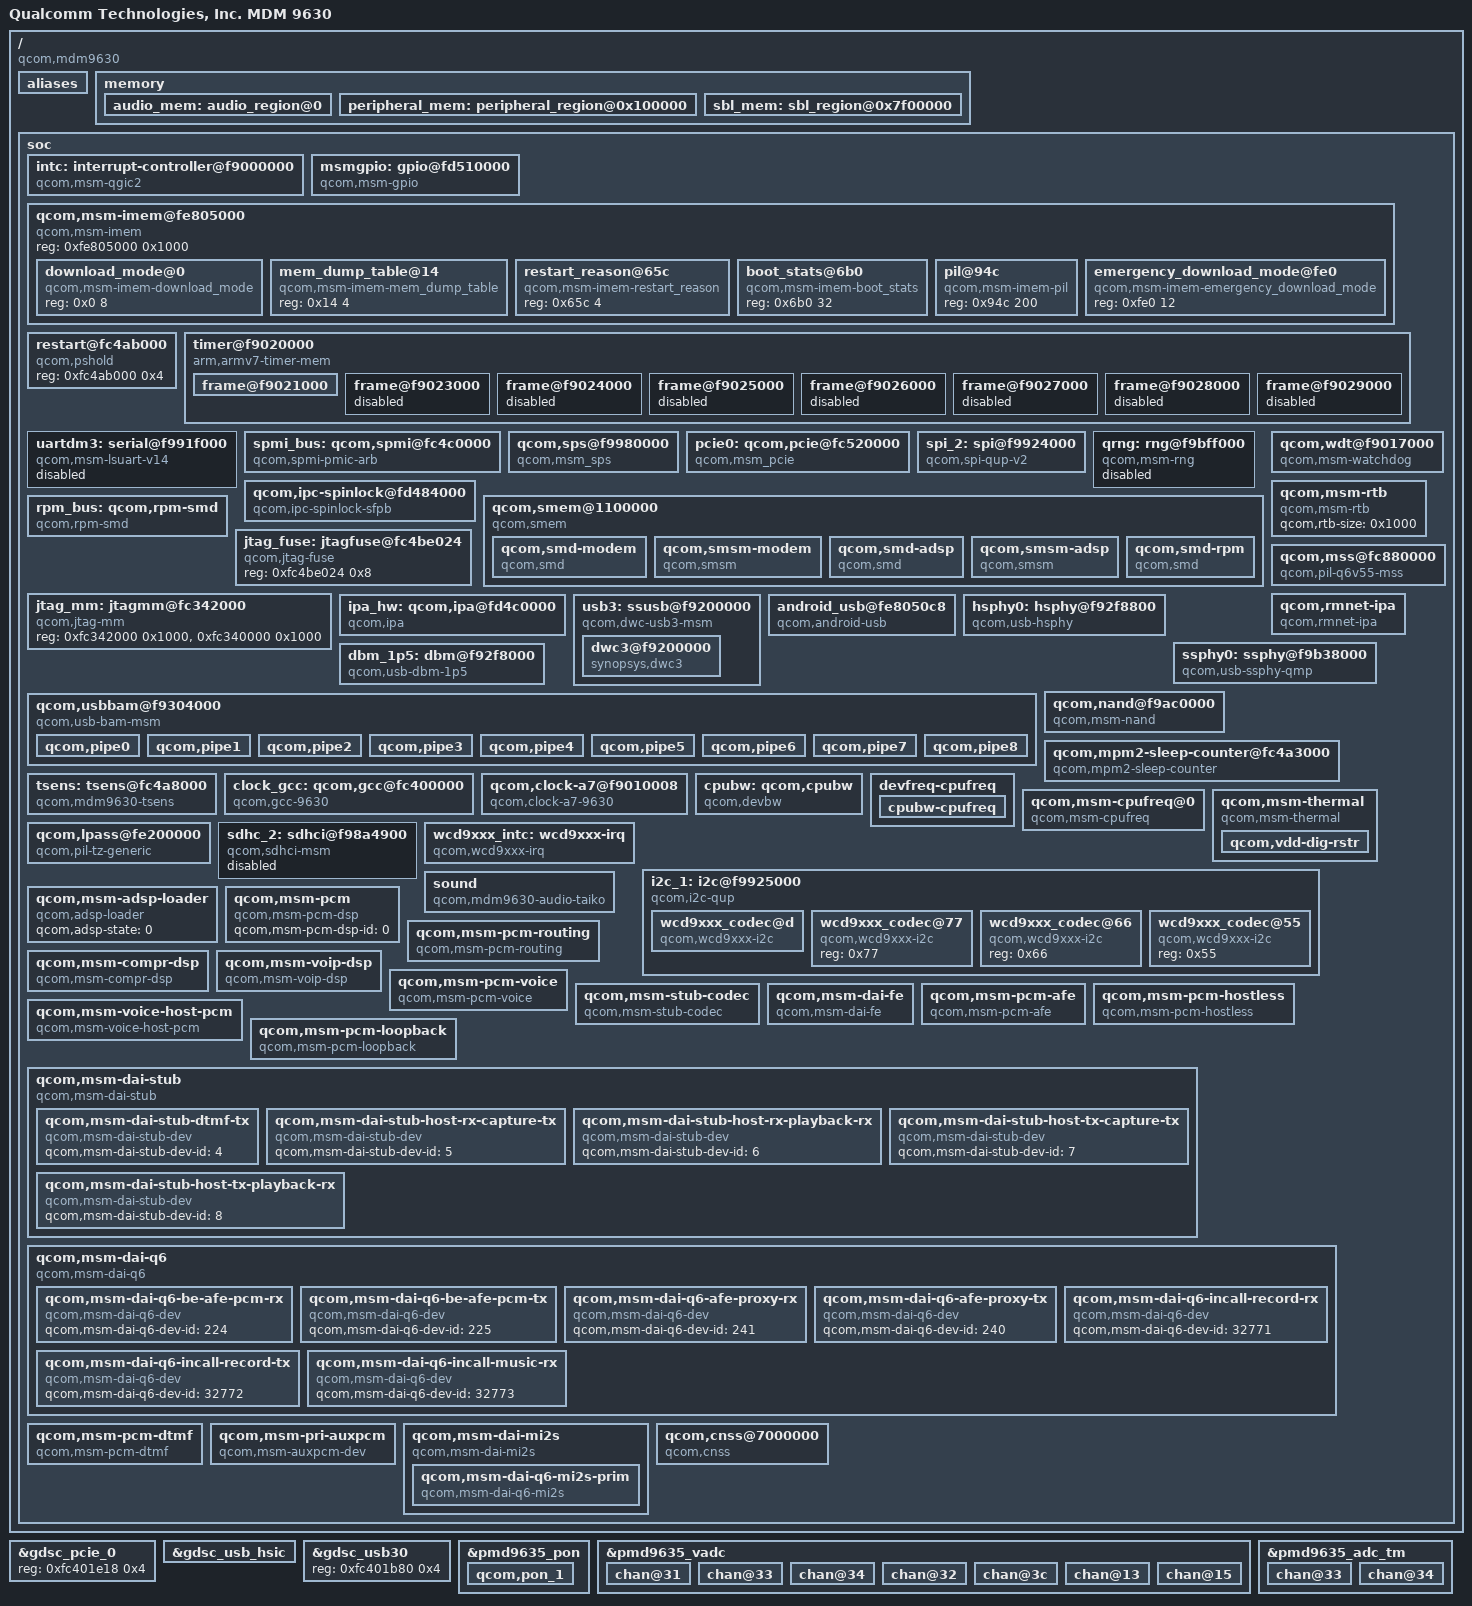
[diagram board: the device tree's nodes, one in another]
/* Copyright (c) 2013-2014, The Linux Foundation. All rights reserved.
 *
 * This program is free software; you can redistribute it and/or modify
 * it under the terms of the GNU General Public License version 2 and
 * only version 2 as published by the Free Software Foundation.
 *
 * This program is distributed in the hope that it will be useful,
 * but WITHOUT ANY WARRANTY; without even the implied warranty of
 * MERCHANTABILITY or FITNESS FOR A PARTICULAR PURPOSE.  See the
 * GNU General Public License for more details.
 */

#include "skeleton.dtsi"

/ {
	model = "Qualcomm Technologies, Inc. MDM 9630";
	compatible = "qcom,mdm9630";
	qcom,msm-id = <187 0x10000>, <227 0x10000>, <228 0x10000>,
		      <229 0x10000>, <230 0x10000>, <231 0x10000>;
	interrupt-parent = <&intc>;

	aliases {
		spi2 = &spi_2;
		sdhc2 = &sdhc_2; /* SDC2 SD card slot */
	};

	memory {
		audio_mem: audio_region@0 {
			linux,reserve-contiguous-region;
			linux,reserve-region;
			reg = <0 0xAF000>;
			label = "audio_mem";
		};

		peripheral_mem: peripheral_region@0x100000 {
			linux,reserve-contiguous-region;
			linux,reserve-region;
			linux,remove-completely;
			reg = <0x1000000 0x6100000>;
			label = "peripheral_mem";
		};

		sbl_mem: sbl_region@0x7f00000 {
			linux,reserve-contiguous-region;
			linux,reserve-region;
			linux,remove-completely;
			reg = <0x7f00000 0x100000>;
			label = "sbl_mem";
		};
	};

	soc: soc { };
};

#include "mdm9630-smp2p.dtsi"
#include "mdm9630-coresight.dtsi"
#include "msm-gdsc.dtsi"
#include "mdm9630-pm.dtsi"
#include "mdm9630-bus.dtsi"
#include "mdm9630-ion.dtsi"
#include "mdm9630-pinctrl.dtsi"

&soc {
	#address-cells = <1>;
	#size-cells = <1>;
	ranges;

	intc: interrupt-controller@f9000000 {
		compatible = "qcom,msm-qgic2";
		interrupt-controller;
		#interrupt-cells = <3>;
		reg = <0xf9000000 0x1000>,
		      <0xf9002000 0x1000>;
	};

	msmgpio: gpio@fd510000 {
		compatible = "qcom,msm-gpio";
		gpio-controller;
		#gpio-cells = <2>;
		interrupt-controller;
		#interrupt-cells = <2>;
		reg = <0xfd510000 0x4000>;
		ngpio = <90>;
		interrupts = <0 208 0>;
		qcom,direct-connect-irqs = <8>;
	};

	qcom,msm-imem@fe805000 {
		compatible = "qcom,msm-imem";
		reg = <0xfe805000 0x1000>; /* Address and size of IMEM */
		ranges = <0x0 0xfe805000 0x1000>;
		#address-cells = <1>;
		#size-cells = <1>;

		download_mode@0 {
			compatible = "qcom,msm-imem-download_mode";
			reg = <0x0 8>;
		};

		mem_dump_table@14 {
			compatible = "qcom,msm-imem-mem_dump_table";
			reg = <0x14 4>;
		};

		restart_reason@65c {
			compatible = "qcom,msm-imem-restart_reason";
			reg = <0x65c 4>;
		};

		boot_stats@6b0 {
			compatible = "qcom,msm-imem-boot_stats";
			reg = <0x6b0 32>;
		};

		pil@94c {
			compatible = "qcom,msm-imem-pil";
			reg = <0x94c 200>;
		};

		emergency_download_mode@fe0 {
			compatible = "qcom,msm-imem-emergency_download_mode";
			reg = <0xfe0 12>;
		};
	};

	restart@fc4ab000 {
		compatible = "qcom,pshold";
		reg = <0xfc4ab000 0x4>;
	};

	timer@f9020000 {
		#address-cells = <1>;
		#size-cells = <1>;
		ranges;
		compatible = "arm,armv7-timer-mem";
		reg = <0xf9020000 0x1000>;
		clock-frequency = <19200000>;

		frame@f9021000 {
			frame-number = <0>;
			interrupts = <0 7 0x4>,
				     <0 6 0x4>;
			reg = <0xf9021000 0x1000>,
			      <0xf9022000 0x1000>;
		};

		frame@f9023000 {
			frame-number = <1>;
			interrupts = <0 8 0x4>;
			reg = <0xf9023000 0x1000>;
			status = "disabled";
		};

		frame@f9024000 {
			frame-number = <2>;
			interrupts = <0 9 0x4>;
			reg = <0xf9024000 0x1000>;
			status = "disabled";
		};

		frame@f9025000 {
			frame-number = <3>;
			interrupts = <0 10 0x4>;
			reg = <0xf9025000 0x1000>;
			status = "disabled";
		};

		frame@f9026000 {
			frame-number = <4>;
			interrupts = <0 11 0x4>;
			reg = <0xf9026000 0x1000>;
			status = "disabled";
		};

		frame@f9027000 {
			frame-number = <5>;
			interrupts = <0 12 0x4>;
			reg = <0xf9027000 0x1000>;
			status = "disabled";
		};

		frame@f9028000 {
			frame-number = <6>;
			interrupts = <0 13 0x4>;
			reg = <0xf9028000 0x1000>;
			status = "disabled";
		};

		frame@f9029000 {
			frame-number = <7>;
			interrupts = <0 14 0x4>;
			reg = <0xf9029000 0x1000>;
			status = "disabled";
		};
	};

	uartdm3: serial@f991f000 {
		compatible = "qcom,msm-lsuart-v14";
		reg = <0xf991f000 0x1000>;
		interrupts = <0 109 0>;
		status = "disabled";
	};

	spmi_bus: qcom,spmi@fc4c0000 {
		compatible = "qcom,spmi-pmic-arb";
		reg = <0xfc4cf000 0x1000>,
		      <0Xfc4cb000 0x1000>,
		      <0Xfc4ca000 0x1000>;
		reg-names = "core", "intr", "cnfg";
		interrupts = <0 190 0>;
		qcom,pmic-arb-channel = <0>;
		qcom,pmic-arb-ee = <0>;
		#interrupt-cells = <3>;
		interrupt-controller;
		#address-cells = <1>;
		#size-cells = <0>;
		cell-index = <0>;
	};

	qcom,sps@f9980000 {
		compatible = "qcom,msm_sps";
		reg = <0xf9984000 0x15000>,
		      <0xf9999000 0xb000>,
		      <0xfe803000 0xd000>,
			  <0xfe805000 0x1000>;
		interrupts = <0 94 0>;
	};

	pcie0: qcom,pcie@fc520000 {
		compatible = "qcom,msm_pcie";
		cell-index = <0>;
		qcom,ctrl-amt = <1>;

		reg = <0xfc520000 0x2000>,
		      <0xfc526000 0x1000>,
		      <0x80000000 0x1000>,
		      <0x80001000 0x1000>,
		      <0x80100000 0x1000>,
		      <0x80200000 0x100000>,
		      <0x80300000 0xd00000>;
		reg-names = "parf", "phy", "dm_core", "elbi",
				"conf", "io", "bars";

		#address-cells = <0>;
		interrupt-parent = <&pcie0>;
		interrupts = <0 1 2 3 4 5 6 7 8 9 10 11 12>;
		#interrupt-cells = <1>;
		interrupt-map-mask = <0xffffffff>;
		interrupt-map = <0 &intc 0 41 0
				1 &intc 0 42 0
				2 &intc 0 43 0
				3 &intc 0 44 0
				4 &intc 0 45 0
				5 &intc 0 46 0
				6 &intc 0 47 0
				7 &intc 0 48 0
				8 &intc 0 49 0
				9 &intc 0 50 0
				10 &intc 0 51 0
				11 &intc 0 52 0
				12 &msmgpio 65 0x2>;
		interrupt-names = "int_msi", "int_a", "int_b", "int_c", "int_d",
				"int_pls_pme", "int_pme_legacy", "int_pls_err",
				"int_aer_legacy", "int_pls_link_up",
				"int_pls_link_down", "int_bridge_flush_n",
				"int_wake";

		perst-gpio = <&msmgpio 61 0>;
		wake-gpio = <&msmgpio 65 0>;
		clkreq-gpio = <&msmgpio 64 0>;

		gdsc-vdd-supply = <&gdsc_pcie_0>;
		vreg-1.8-supply = <&pmd9635_l8>;
		vreg-0.9-supply = <&pmd9635_l4>;

		qcom,vreg-1.8-voltage-level = <1800000 1800000 1000>;
		qcom,vreg-0.9-voltage-level = <950000 950000 24000>;

		clock-names = "pcie_0_pipe_clk", "pcie_0_ref_clk_src",
				"pcie_0_aux_clk", "pcie_0_cfg_ahb_clk",
				"pcie_0_mstr_axi_clk", "pcie_0_slv_axi_clk",
				"pcie_0_ldo";
		max-clock-frequency-hz = <125000000>, <0>, <1000000>,
						<0>, <0>, <0>, <0>;

		qcom,msm-bus,name = "pcie0";
		qcom,msm-bus,num-cases = <2>;
		qcom,msm-bus,num-paths = <1>;
		qcom,msm-bus,vectors-KBps =
				<45 512 0 0>,
				<45 512 500 800>;
	};

	spi_2: spi@f9924000 { /* BLSP1 QUP2 */
		compatible = "qcom,spi-qup-v2";
		#address-cells = <1>;
		#size-cells = <0>;
		reg-names = "spi_physical", "spi_bam_physical";
		reg = <0xf9924000 0x1000>,
		      <0xf9904000 0x19000>;
		interrupt-names = "spi_irq", "spi_bam_irq";
		interrupts = <0 96 0>, <0 238 0>;
		spi-max-frequency = <2400000>;

		qcom,gpio-mosi = <&msmgpio 4 0>;
		qcom,gpio-miso = <&msmgpio 5 0>;
		qcom,gpio-clk  = <&msmgpio 7 0>;
		qcom,gpio-cs0  = <&msmgpio 6 0>;

		qcom,infinite-mode = <0>;
		qcom,use-bam;
		qcom,ver-reg-exists;
		qcom,bam-consumer-pipe-index = <14>;
		qcom,bam-producer-pipe-index = <15>;
		qcom,master-id = <86>;
	};

	qrng: rng@f9bff000 {
		compatible = "qcom,msm-rng";
		reg = <0xf9bff000 0x200>;
		qcom,msm-rng-iface-clk;
		qcom,msm-bus,name = "msm-rng-noc";
		qcom,msm-bus,num-cases = <2>;
		qcom,msm-bus,num-paths = <1>;
		qcom,msm-bus,vectors-KBps =
				<1 618 0 0>,
				<1 618 0 800>;
		status = "disabled";
	};

	qcom,ipc-spinlock@fd484000 {
		compatible = "qcom,ipc-spinlock-sfpb";
		reg = <0xfd484000 0x400>;
		qcom,num-locks = <8>;
	};

	qcom,smem@1100000 {
		compatible = "qcom,smem";
		reg = <0x1100000 0x100000>,
			<0xf9011000 0x1000>,
			<0xfc428000 0x4000>;
		reg-names = "smem", "irq-reg-base", "aux-mem1";
		qcom,mpu-enabled;

		qcom,smd-modem {
			compatible = "qcom,smd";
			qcom,smd-edge = <0>;
			qcom,smd-irq-offset = <0x8>;
			qcom,smd-irq-bitmask = <0x1000>;
			interrupts = <0 25 1>;
			label = "modem";
		};

		qcom,smsm-modem {
			compatible = "qcom,smsm";
			qcom,smsm-edge = <0>;
			qcom,smsm-irq-offset = <0x8>;
			qcom,smsm-irq-bitmask = <0x2000>;
			interrupts = <0 26 1>;
		};

		qcom,smd-adsp {
			compatible = "qcom,smd";
			qcom,smd-edge = <1>;
			qcom,smd-irq-offset = <0x8>;
			qcom,smd-irq-bitmask = <0x100>;
			interrupts = <0 156 1>;
			label = "adsp";
		};

		qcom,smsm-adsp {
			compatible = "qcom,smsm";
			qcom,smsm-edge = <1>;
			qcom,smsm-irq-offset = <0x8>;
			qcom,smsm-irq-bitmask = <0x200>;
			interrupts = <0 157 1>;
		};

		qcom,smd-rpm {
			compatible = "qcom,smd";
			qcom,smd-edge = <15>;
			qcom,smd-irq-offset = <0x8>;
			qcom,smd-irq-bitmask = <0x1>;
			interrupts = <0 168 1>;
			label = "rpm";
			qcom,irq-no-suspend;
			qcom,not-loadable;
		};
	};

	rpm_bus: qcom,rpm-smd {
		compatible = "qcom,rpm-smd";
		rpm-channel-name = "rpm_requests";
		rpm-channel-type = <15>; /* SMD_APPS_RPM */
	};

	qcom,wdt@f9017000 {
		compatible = "qcom,msm-watchdog";
		reg = <0xf9017000 0x1000>;
		reg-names = "wdt-base";
		interrupts = <1 2 0>, <1 1 0>;
		qcom,bark-time = <11000>;
		qcom,pet-time = <10000>;
	};

	jtag_fuse: jtagfuse@fc4be024 {
		compatible = "qcom,jtag-fuse";
		reg = <0xfc4be024 0x8>;
		reg-names = "fuse-base";
	};

	jtag_mm: jtagmm@fc342000 {
		compatible = "qcom,jtag-mm";
		reg = <0xfc342000 0x1000>,
		      <0xfc340000 0x1000>;
		reg-names = "etm-base","debug-base";
	};

	qcom,msm-rtb {
		compatible = "qcom,msm-rtb";
		qcom,rtb-size = <0x1000>; /* 4K EBI1 buffer */
	};

	qcom,mss@fc880000 {
		compatible = "qcom,pil-q6v55-mss";
		reg = <0xfc880000 0x100>,
		      <0xfd485000 0x400>,
		      <0xfc820000 0x020>,
		      <0xfc401680 0x004>;
		reg-names = "qdsp6_base", "halt_base", "rmb_base",
			    "restart_reg";

		interrupts = <0 24 1>;
		vdd_mss-supply = <&pmd9635_s1>;
		vdd_cx-supply = <&pmd9635_l3_corner>;
		vdd_mx-supply = <&pmd9635_s3>;
		vdd_mx-uV = <7>;
		vdd_pll-supply = <&pmd9635_l7>;
		qcom,vdd_pll = <1800000>;

		qcom,firmware-name = "modem";
		qcom,pil-self-auth;
		qcom,mba-image-is-not-elf;

		/* GPIO inputs from mss */
		qcom,gpio-err-fatal = <&smp2pgpio_ssr_smp2p_1_in 0 0>;
		qcom,gpio-err-ready = <&smp2pgpio_ssr_smp2p_1_in 1 0>;
		qcom,gpio-proxy-unvote = <&smp2pgpio_ssr_smp2p_1_in 2 0>;
		qcom,gpio-stop-ack = <&smp2pgpio_ssr_smp2p_1_in 3 0>;

		/* GPIO output to mss */
		qcom,gpio-force-stop = <&smp2pgpio_ssr_smp2p_1_out 0 0>;
	};

	ipa_hw: qcom,ipa@fd4c0000 {
		compatible = "qcom,ipa";
		reg = <0xfd4c0000 0x29000>,
		      <0xfd4c4000 0x15820>;
		reg-names = "ipa-base", "bam-base";
		interrupts = <0 252 0>,
		             <0 254 0>;
		interrupt-names = "ipa-irq", "bam-irq";
		qcom,ipa-hw-ver = <3>; /* IPA core version = IPAv2.0 */
		qcom,ipa-hw-mode = <0>; /* IPA hw type = Normal */
		qcom,ee = <2>;
		qcom,use-ipa-tethering-bridge;
	};

	qcom,rmnet-ipa {
		compatible = "qcom,rmnet-ipa";
	};

	usb3: ssusb@f9200000 {
		compatible = "qcom,dwc-usb3-msm";
		reg = <0xf9200000 0xfc000>,
				<0xfd4ab000 0x4>;
		#address-cells = <1>;
		#size-cells = <1>;
		ranges;

		interrupt-parent = <&usb3>;
		interrupts = <0 1 2>;
		#interrupt-cells = <1>;
		interrupt-map-mask = <0x0 0xffffffff>;
		interrupt-map = <0x0 0 &intc 0 133 0
				 0x0 1 &intc 0 180 0
				 0x0 2 &spmi_bus 0x0 0x0 0x9 0x0>;
		interrupt-names = "hs_phy_irq", "pwr_event_irq",
				"pmic_id_irq";

		USB3_GDSC-supply = <&gdsc_usb30>;
		qcom,otg-capability;
		qcom,suspend_event_enable;
		qcom,usb-dbm = <&dbm_1p5>;

		qcom,msm-bus,name = "usb3";
		qcom,msm-bus,num-cases = <2>;
		qcom,msm-bus,num-paths = <1>;
		qcom,msm-bus,vectors-KBps =
						<61 512 0 0>,
						<61 512 240000 960000>;
		qcom,reset_hsphy_sleep_clk_on_init;
		qcom,power-collapse-on-cable-disconnect;
		qcom,por-after-power-collapse;

		dwc3@f9200000 {
				compatible = "synopsys,dwc3";
				reg = <0xf9200000 0xfc000>;
				interrupt-parent = <&intc>;
				interrupts = <0 131 0>, <0 179 0>;
				interrupt-names = "irq", "otg_irq";
				usb-phy = <&hsphy0>, <&ssphy0>;
				snps,nominal-elastic-buffer;
				snps,core-reset-after-phy-init;
				snps,hsphy-auto-suspend-disable;
				snps,hird_thresh = <0x10>;
		};
        };

	android_usb@fe8050c8 {
		reg = <0xfe8050c8 0xc8>;
		compatible = "qcom,android-usb";
		qcom,android-usb-swfi-latency = <100>;
	};

	hsphy0: hsphy@f92f8800 {
		compatible = "qcom,usb-hsphy";
		reg = <0xf92f8800 0x3ff>;
		qcom,hsphy-init = <0x00D191A4>;
		vdd-supply = <&pmd9635_l3_corner>;
		vdda18-supply = <&pmd9635_l8>;
		vdda33-supply = <&pmd9635_l10>;
		qcom,vdd-voltage-level = <1 5 7>;
		qcom,ext-vbus-id;
		qcom,vbus-valid-override;
		qcom,set-pllbtune;
	};

	ssphy0: ssphy@f9b38000 {
		compatible = "qcom,usb-ssphy-qmp";
		reg = <0xf9b38000 0x16c>,
			<0xf9b3e000 0x3ff>;
		reg-names = "qmp_phy_base",
			"qmp_ahb2phy_base";
		vdd-supply = <&pmd9635_l4>;
		vdda18-supply = <&pmd9635_l8>;
		qcom,vdd-voltage-level = <0 900000 1050000>;
		qcom,vbus-valid-override;
		qcom,ext-vbus-id;
	};

	dbm_1p5: dbm@f92f8000 {
		compatible = "qcom,usb-dbm-1p5";
		reg = <0xf92f8000 0x1000>;
		qcom,reset-ep-after-lpm-resume;
	};

	qcom,usbbam@f9304000 {
		compatible = "qcom,usb-bam-msm";
		reg = <0xf9304000 0x8814>;
		reg-names = "ssusb";
		interrupts = <0 132 0>;
		interrupt-names = "ssusb";
		qcom,usb-bam-fifo-baseaddr = <0xfe803000>;
		qcom,usb-bam-num-pipes = <16>;
		qcom,ignore-core-reset-ack;
		qcom,disable-clk-gating;
		qcom,usb-bam-override-threshold = <0x4001>;
		qcom,usb-bam-max-mbps-highspeed = <400>;
		qcom,usb-bam-max-mbps-superspeed = <3600>;

		qcom,pipe0 {
			label = "ssusb-ipa-out-0";
			qcom,usb-bam-mem-type = <2>;
			qcom,bam-type = <0>;
			qcom,dir = <0>;
			qcom,pipe-num = <0>;
			qcom,peer-bam = <2>;
			qcom,src-bam-physical-address = <0xf9304000>;
			qcom,src-bam-pipe-index = <1>;
			qcom,data-fifo-size = <0x8000>;
			qcom,descriptor-fifo-size = <0x2000>;
			qcom,reset-bam-on-connect;
			qcom,pipe-connection-type = <1>;
		};
		qcom,pipe1 {
			label = "ssusb-ipa-in-0";
			qcom,usb-bam-mem-type = <2>;
			qcom,bam-type = <0>;
			qcom,dir = <1>;
			qcom,pipe-num = <0>;
			qcom,peer-bam = <2>;
			qcom,dst-bam-physical-address = <0xf9304000>;
			qcom,dst-bam-pipe-index = <0>;
			qcom,data-fifo-size = <0x8000>;
			qcom,descriptor-fifo-size = <0x2000>;
			qcom,reset-bam-on-connect;
		};
		qcom,pipe2 {
			label = "ssusb-qdss-in-0";
			qcom,usb-bam-mem-type = <3>;
			qcom,bam-type = <0>;
			qcom,dir = <1>;
			qcom,pipe-num = <0>;
			qcom,peer-bam = <1>;
			qcom,src-bam-physical-address = <0xfc37C000>;
			qcom,src-bam-pipe-index = <0>;
			qcom,dst-bam-physical-address = <0xf9304000>;
			qcom,dst-bam-pipe-index = <2>;
			qcom,data-fifo-offset = <0x0>;
			qcom,data-fifo-size = <0xC00>;
			qcom,descriptor-fifo-offset = <0xC00>;
			qcom,descriptor-fifo-size = <0x400>;
			qcom,reset-bam-on-connect;
		};
		qcom,pipe3 {
			label = "ssusb-ipa-out-1";
			qcom,usb-bam-mem-type = <2>;
			qcom,bam-type = <0>;
			qcom,dir = <0>;
			qcom,pipe-num = <1>;
			qcom,peer-bam = <2>;
			qcom,src-bam-physical-address = <0xf9304000>;
			qcom,src-bam-pipe-index = <3>;
			qcom,data-fifo-size = <0x8000>;
			qcom,descriptor-fifo-size = <0x2000>;
			qcom,reset-bam-on-connect;
			qcom,pipe-connection-type = <1>;
		};
		qcom,pipe4 {
			label = "ssusb-ipa-in-1";
			qcom,usb-bam-mem-type = <2>;
			qcom,bam-type = <0>;
			qcom,dir = <1>;
			qcom,pipe-num = <1>;
			qcom,peer-bam = <2>;
			qcom,dst-bam-physical-address = <0xf9304000>;
			qcom,dst-bam-pipe-index = <2>;
			qcom,data-fifo-size = <0x8000>;
			qcom,descriptor-fifo-size = <0x2000>;
			qcom,reset-bam-on-connect;
		};
		qcom,pipe5 {
			label = "ssusb-ipa-out-2";
			qcom,usb-bam-mem-type = <2>;
			qcom,bam-type = <0>;
			qcom,dir = <0>;
			qcom,pipe-num = <2>;
			qcom,peer-bam = <2>;
			qcom,src-bam-physical-address = <0xf9304000>;
			qcom,src-bam-pipe-index = <5>;
			qcom,data-fifo-size = <0x8000>;
			qcom,descriptor-fifo-size = <0x2000>;
			qcom,reset-bam-on-connect;
			qcom,pipe-connection-type = <1>;
		};
		qcom,pipe6 {
			label = "ssusb-ipa-in-2";
			qcom,usb-bam-mem-type = <2>;
			qcom,bam-type = <0>;
			qcom,dir = <1>;
			qcom,pipe-num = <2>;
			qcom,peer-bam = <2>;
			qcom,dst-bam-physical-address = <0xf9304000>;
			qcom,dst-bam-pipe-index = <4>;
			qcom,data-fifo-size = <0x8000>;
			qcom,descriptor-fifo-size = <0x2000>;
			qcom,reset-bam-on-connect;
		};
		qcom,pipe7  {
			label = "ssusb-ipa-out-3";
			qcom,usb-bam-mem-type = <2>;
			qcom,bam-type = <0>;
			qcom,dir = <0>;
			qcom,pipe-num = <3>;
			qcom,peer-bam = <2>;
			qcom,src-bam-physical-address = <0xf9304000>;
			qcom,src-bam-pipe-index = <6>;
			qcom,data-fifo-size = <0x8000>;
			qcom,descriptor-fifo-size = <0x2000>;
			qcom,reset-bam-on-connect;
			qcom,pipe-connection-type = <1>;
		};
		qcom,pipe8  {
			label = "ssusb-ipa-in-3";
			qcom,usb-bam-mem-type = <2>;
			qcom,bam-type = <0>;
			qcom,dir = <1>;
			qcom,pipe-num = <3>;
			qcom,peer-bam = <2>;
			qcom,dst-bam-physical-address = <0xf9304000>;
			qcom,dst-bam-pipe-index = <7>;
			qcom,data-fifo-size = <0x8000>;
			qcom,descriptor-fifo-size = <0x2000>;
			qcom,reset-bam-on-connect;
		};
	};

	qcom,nand@f9ac0000 {
		compatible = "qcom,msm-nand";
		reg = <0xf9ac0000 0x1000>,
		      <0xf9ac4000 0x8000>;
		reg-names = "nand_phys",
			    "bam_phys";
		interrupts = <0 247 0>;
		interrupt-names = "bam_irq";

		qcom,msm-bus,name = "qpic_nand";
		qcom,msm-bus,num-cases = <2>;
		qcom,msm-bus,num-paths = <1>;

		qcom,msm-bus,vectors-KBps =
			<91 512 0 0>,
			/* Voting for max b/w on PNOC bus for now */
			<91 512 400000 800000>;

	};

	qcom,mpm2-sleep-counter@fc4a3000 {
		compatible = "qcom,mpm2-sleep-counter";
		reg = <0xfc4a3000 0x1000>;
		clock-frequency = <32768>;
	};

	tsens: tsens@fc4a8000 {
		compatible = "qcom,mdm9630-tsens";
		reg = <0xfc4a8000 0x2000>,
		      <0xfc4bc000 0x1000>;
		reg-names = "tsens_physical", "tsens_eeprom_physical";
		interrupts = <0 184 0>;
		qcom,sensors = <5>;
		qcom,slope = <2901 2846 3200 3200 3200>;
	};

	clock_gcc: qcom,gcc@fc400000 {
		compatible = "qcom,gcc-9630";
		reg = <0xfc400000 0x4000>,
			<0xf9011000 0x1C>,
			<0xf9008018 0x28>;
		reg-names = "cc_base", "meas", "apcs_base";
		vdd_dig-supply = <&pmd9635_l3_corner>;
		vdd_dig_ao-supply = <&pmd9635_l3_corner_ao>;
	};

	qcom,clock-a7@f9010008 {
		compatible = "qcom,clock-a7-9630";
		reg = <0xf9010008 0x8>;
		reg-names = "rcg-base";

		clock-names = "clk-1", "clk-5";
		qcom,speed0-bin-v0 =
			<         0 0>,
			< 300000000 4>,
			< 787200000 5>,
			<1152000000 7>;

		cpu-vdd-supply = <&pmd9635_l3_corner_ao>;
	};

	cpubw: qcom,cpubw {
		compatible = "qcom,devbw";
		governor = "cpufreq";
		qcom,src-dst-ports = <1 512>;
		qcom,active-only;
		qcom,bw-tbl =
			< 1266 /* 166 MHz */ >,
			< 2540 /* 333 MHz */ >,
			< 3051 /* 400 MHz */ >;
	};

	devfreq-cpufreq {
		cpubw-cpufreq {
			target-dev = <&cpubw>;
			cpu-to-dev-map =
				<  600000 1266 >,
				<  787200 2540 >,
				< 1152000 3051 >;
		};
	};

	qcom,msm-cpufreq@0 {
		reg = <0 4>;
		compatible = "qcom,msm-cpufreq";
		qcom,cpufreq-table =
			<  300000 >,
			<  600000 >,
			<  787200 >,
			<  998400 >,
			< 1152000 >;
	};

	qcom,msm-thermal {
		compatible = "qcom,msm-thermal";
		qcom,sensor-id = <0>;
		qcom,poll-ms = <250>;
		qcom,limit-temp = <60>;
		qcom,temp-hysteresis = <10>;
		qcom,freq-step = <2>;
		qcom,freq-control-mask = <0x0>;
		qcom,mx-restriction-temp = <5>;
		qcom,mx-restriction-temp-hysteresis = <5>;
		qcom,mx-retention-min = <710000>;
		vdd-mx-supply = <&pmd9635_s3>;
		qcom,vdd-restriction-temp = <5>;
		qcom,vdd-restriction-temp-hysteresis = <10>;
		vdd-dig-supply = <&pmd9635_l3_corner>;

		qcom,vdd-dig-rstr{
			qcom,vdd-rstr-reg = "vdd-dig";
			qcom,levels = <5 7 7>; /* Nominal, Super Turbo, Super Turbo */
			qcom,min-level = <1>; /* No Request */
		};
	};

	qcom,lpass@fe200000 {
		compatible = "qcom,pil-tz-generic";
		reg = <0xfe200000 0x00100>;
		interrupts = <0 162 1>;

		vdd_cx-supply = <&pmd9635_l3_corner>;
		qcom,proxy-reg-names = "vdd_cx";
		qcom,vdd_cx-uV-uA = <7 100000>;
		clock-names = "bus_clk", "xo", "scm_core_clk", "scm_iface_clk",
				"scm_bus_clk", "scm_core_clk_src";
		qcom,active-clock-names = "bus_clk";
		qcom,proxy-clock-names = "xo", "scm_core_clk", "scm_iface_clk",
					"scm_bus_clk", "scm_core_clk_src";
		qcom,scm_core_clk_src-freq = <85710000>;

		qcom,pas-id = <1>;
		qcom,proxy-timeout-ms = <10000>;
		qcom,smem-id = <423>;
		qcom,firmware-name = "adsp";

		/* GPIO inputs from lpass */
		qcom,gpio-err-fatal = <&smp2pgpio_ssr_smp2p_2_in 0 0>;
		qcom,gpio-proxy-unvote = <&smp2pgpio_ssr_smp2p_2_in 2 0>;
		qcom,gpio-err-ready = <&smp2pgpio_ssr_smp2p_2_in 1 0>;
		qcom,gpio-stop-ack = <&smp2pgpio_ssr_smp2p_2_in 3 0>;

		/* GPIO output to lpass */
		qcom,gpio-force-stop = <&smp2pgpio_ssr_smp2p_2_out 0 0>;
	};

	sdhc_2: sdhci@f98a4900 {
		compatible = "qcom,sdhci-msm";
		reg = <0xf98a4900 0x11c>, <0xf98a4000 0x800>;
		reg-names = "hc_mem", "core_mem";
		interrupts = <0 125 0>, <0 221 0>;
		interrupt-names = "hc_irq", "pwr_irq";

		qcom,clk-rates = <400000 20000000 25000000 50000000 100000000 200000000>;
		qcom,bus-width = <4>;
		qcom,cpu-dma-latency-us = <200>;
		status = "disable";
	};

	wcd9xxx_intc: wcd9xxx-irq {
		compatible = "qcom,wcd9xxx-irq";
		interrupt-controller;
		#interrupt-cells = <1>;
		interrupt-parent = <&msmgpio>;
		interrupts = <43 0>;
		interrupt-names = "cdc-int";
	};

	i2c_1: i2c@f9925000 { /* BLSP1 QUP3 */
		cell-index = <1>;
		compatible = "qcom,i2c-qup";
		#address-cells = <1>;
		#size-cells = <0>;
		reg-names = "qup_phys_addr";
		reg = <0xf9925000 0x1000>;
		interrupt-names = "qup_err_intr";
		interrupts = <0 97 0>;
		qcom,i2c-bus-freq = <400000>;
		qcom,i2c-src-freq = <19200000>;
		qcom,sda-gpio = <&msmgpio 10 0>;
		qcom,scl-gpio = <&msmgpio 11 0>;
		qcom,master-id = <86>;

		wcd9xxx_codec@d{
			compatible = "qcom,wcd9xxx-i2c";
			reg = <0x0d>;
			qcom,cdc-reset-gpio = <&msmgpio 67 0>;
			interrupt-parent = <&wcd9xxx_intc>;
			interrupts = <0 1 2 3 4 5 6 7 8 9 10 11 12 13 14 15 16 17 18 19 20 21 22 23 24 25 26 27 28>;
			cdc-vdd-buck-supply = <&pmd9635_s4>;
			qcom,cdc-vdd-buck-voltage = <1800000 1800000>;
			qcom,cdc-vdd-buck-current = <25000>;

			cdc-vdd-tx-h-supply = <&pmd9635_l15>;
			qcom,cdc-vdd-tx-h-voltage = <1800000 1800000>;
			qcom,cdc-vdd-tx-h-current = <25000>;

			cdc-vdd-rx-h-supply = <&pmd9635_l15>;
			qcom,cdc-vdd-rx-h-voltage = <1800000 1800000>;
			qcom,cdc-vdd-rx-h-current = <25000>;

			cdc-vddpx-1-supply = <&pmd9635_l6>;
			qcom,cdc-vddpx-1-voltage = <1800000 1800000>;
			qcom,cdc-vddpx-1-current = <10000>;

			cdc-vdd-a-1p2v-supply = <&pmd9635_l1>;
			qcom,cdc-vdd-a-1p2v-voltage = <1225000 1225000>;
			qcom,cdc-vdd-a-1p2v-current = <10000>;

			cdc-vddcx-1-supply = <&pmd9635_l2>;
			qcom,cdc-vddcx-1-voltage = <1200000 1200000>;
			qcom,cdc-vddcx-1-current = <10000>;

			cdc-vddcx-2-supply = <&pmd9635_l2>;
			qcom,cdc-vddcx-2-voltage = <1200000 1200000>;
			qcom,cdc-vddcx-2-current = <10000>;

			qcom,cdc-static-supplies = "cdc-vdd-buck",
						   "cdc-vdd-tx-h",
						   "cdc-vdd-rx-h",
						   "cdc-vddpx-1",
						   "cdc-vdd-a-1p2v",
						   "cdc-vddcx-1",
						   "cdc-vddcx-2";

			qcom,cdc-micbias-ldoh-v = <0x3>;
			qcom,cdc-micbias-cfilt1-mv = <1800>;
			qcom,cdc-micbias-cfilt2-mv = <2700>;
			qcom,cdc-micbias-cfilt3-mv = <1800>;
			qcom,cdc-micbias1-cfilt-sel = <0x0>;
			qcom,cdc-micbias2-cfilt-sel = <0x1>;
			qcom,cdc-micbias3-cfilt-sel = <0x2>;
			qcom,cdc-micbias4-cfilt-sel = <0x2>;
			qcom,cdc-mclk-clk-rate = <12288000>;
		};

		wcd9xxx_codec@77{
			compatible = "qcom,wcd9xxx-i2c";
			reg = <0x77>;
		};

		wcd9xxx_codec@66{
			compatible = "qcom,wcd9xxx-i2c";
			reg = <0x66>;
		};

		wcd9xxx_codec@55{
			compatible = "qcom,wcd9xxx-i2c";
			reg = <0x55>;
		};
	};

	sound {
		compatible = "qcom,mdm9630-audio-taiko";
		qcom,model = "mdm9630-taiko-i2s-snd-card";

		qcom,audio-routing =
			"RX_BIAS", "MCLK",
			"LDO_H", "MCLK",
			"Ext Spk Bottom Pos", "LINEOUT1",
			"Ext Spk Bottom Neg", "LINEOUT3",
			"Ext Spk Top Pos", "LINEOUT2",
			"Ext Spk Top Neg", "LINEOUT4",
			"AMIC1", "MIC BIAS1 External",
			"MIC BIAS1 External", "Handset Mic",
			"AMIC2", "MIC BIAS2 External",
			"MIC BIAS2 External", "Headset Mic",
			"AMIC3", "MIC BIAS3 Internal1",
			"MIC BIAS3 Internal1", "ANCRight Headset Mic",
			"AMIC4", "MIC BIAS1 Internal2",
			"MIC BIAS1 Internal2", "ANCLeft Headset Mic",
			"DMIC1", "MIC BIAS1 External",
			"MIC BIAS1 External", "Digital Mic1",
			"DMIC2", "MIC BIAS1 External",
			"MIC BIAS1 External", "Digital Mic2",
			"DMIC3", "MIC BIAS3 External",
			"MIC BIAS3 External", "Digital Mic3",
			"DMIC4", "MIC BIAS3 External",
			"MIC BIAS3 External", "Digital Mic4",
			"DMIC5", "MIC BIAS4 External",
			"MIC BIAS4 External", "Digital Mic5",
			"DMIC6", "MIC BIAS4 External",
			"MIC BIAS4 External", "Digital Mic6";
			qcom,taiko-mclk-clk-freq = <12288000>;
			qcom,prim-i2s-gpio-ws   = <&msmgpio 12 0>;
			qcom,prim-i2s-gpio-din  = <&msmgpio 13 0>;
			qcom,prim-i2s-gpio-dout = <&msmgpio 14 0>;
			qcom,prim-i2s-gpio-sclk = <&msmgpio 15 0>;
			qcom,prim-i2s-gpio-mclk = <&msmgpio 71 0>;
	};

	qcom,msm-adsp-loader {
		compatible = "qcom,adsp-loader";
		qcom,adsp-state = <0>;
	};

	qcom,msm-pcm {
		compatible = "qcom,msm-pcm-dsp";
		qcom,msm-pcm-dsp-id = <0>;
	};

	qcom,msm-pcm-routing {
		compatible = "qcom,msm-pcm-routing";
	};

	qcom,msm-compr-dsp {
		compatible = "qcom,msm-compr-dsp";
	};

	qcom,msm-voip-dsp {
		compatible = "qcom,msm-voip-dsp";
	};

	qcom,msm-pcm-voice {
		compatible = "qcom,msm-pcm-voice";
	};

	qcom,msm-stub-codec {
		compatible = "qcom,msm-stub-codec";
	};

	qcom,msm-dai-fe {
		compatible = "qcom,msm-dai-fe";
	};

	qcom,msm-pcm-afe {
		compatible = "qcom,msm-pcm-afe";
	};

	qcom,msm-pcm-hostless {
		compatible = "qcom,msm-pcm-hostless";
	};

	qcom,msm-voice-host-pcm {
		compatible = "qcom,msm-voice-host-pcm";
	};

	qcom,msm-pcm-loopback {
		compatible = "qcom,msm-pcm-loopback";
	};

	qcom,msm-dai-stub {
		compatible = "qcom,msm-dai-stub";
		qcom,msm-dai-stub-dtmf-tx {
			compatible = "qcom,msm-dai-stub-dev";
			qcom,msm-dai-stub-dev-id = <4>;
		};

		qcom,msm-dai-stub-host-rx-capture-tx {
			compatible = "qcom,msm-dai-stub-dev";
			qcom,msm-dai-stub-dev-id = <5>;
		};

		qcom,msm-dai-stub-host-rx-playback-rx {
			compatible = "qcom,msm-dai-stub-dev";
			qcom,msm-dai-stub-dev-id = <6>;
	       };

		qcom,msm-dai-stub-host-tx-capture-tx {
			compatible = "qcom,msm-dai-stub-dev";
			qcom,msm-dai-stub-dev-id = <7>;
		};

		qcom,msm-dai-stub-host-tx-playback-rx {
			compatible = "qcom,msm-dai-stub-dev";
			qcom,msm-dai-stub-dev-id = <8>;
		};
	};

	qcom,msm-dai-q6 {
		compatible = "qcom,msm-dai-q6";
		qcom,msm-dai-q6-be-afe-pcm-rx {
			compatible = "qcom,msm-dai-q6-dev";
			qcom,msm-dai-q6-dev-id = <224>;
		};

		qcom,msm-dai-q6-be-afe-pcm-tx {
			compatible = "qcom,msm-dai-q6-dev";
			qcom,msm-dai-q6-dev-id = <225>;
		};

		qcom,msm-dai-q6-afe-proxy-rx {
			compatible = "qcom,msm-dai-q6-dev";
			qcom,msm-dai-q6-dev-id = <241>;
		};

		qcom,msm-dai-q6-afe-proxy-tx {
			compatible = "qcom,msm-dai-q6-dev";
			qcom,msm-dai-q6-dev-id = <240>;
		};

		qcom,msm-dai-q6-incall-record-rx {
			compatible = "qcom,msm-dai-q6-dev";
			qcom,msm-dai-q6-dev-id = <32771>;
		};

		qcom,msm-dai-q6-incall-record-tx {
			compatible = "qcom,msm-dai-q6-dev";
			qcom,msm-dai-q6-dev-id = <32772>;
		};

		qcom,msm-dai-q6-incall-music-rx {
			compatible = "qcom,msm-dai-q6-dev";
			qcom,msm-dai-q6-dev-id = <32773>;
		};
	};

	qcom,msm-pcm-dtmf {
		compatible = "qcom,msm-pcm-dtmf";
	};

	qcom,msm-stub-codec {
		compatible = "qcom,msm-stub-codec";
	};

	qcom,msm-pri-auxpcm {
		compatible = "qcom,msm-auxpcm-dev";
		qcom,msm-cpudai-auxpcm-mode = <0>, <0>;
		qcom,msm-cpudai-auxpcm-sync = <1>, <1>;
		qcom,msm-cpudai-auxpcm-frame = <5>, <4>;
		qcom,msm-cpudai-auxpcm-quant = <2>, <2>;
		qcom,msm-cpudai-auxpcm-num-slots = <1>, <1>;
		qcom,msm-cpudai-auxpcm-slot-mapping = <1>, <1>;
		qcom,msm-cpudai-auxpcm-data = <0>, <0>;
		qcom,msm-cpudai-auxpcm-pcm-clk-rate = <2048000>, <2048000>;
		qcom,msm-auxpcm-interface = "primary";
	};

	qcom,msm-dai-mi2s {
		compatible = "qcom,msm-dai-mi2s";
		qcom,msm-dai-q6-mi2s-prim {
			compatible = "qcom,msm-dai-q6-mi2s";
			qcom,msm-dai-q6-mi2s-dev-id = <0>;
			qcom,msm-mi2s-rx-lines = <2>;
			qcom,msm-mi2s-tx-lines = <1>;
		};
	};

	qcom,msm-dai-q6 {
		compatible = "qcom,msm-dai-q6";
	};

	qcom,cnss@7000000 {
		compatible = "qcom,cnss";
		wlan-en-gpio = <&msmgpio 70 0>;
		vdd-wlan-supply = <&wlan_vreg>;
		reg = <0x07000000 0x100000>;
		reg-names = "ramdump";
		qcom,notify-modem-status;
	};
};

&gdsc_pcie_0 {
	status = "ok";
	reg = <0xfc401e18 0x4>;
};

&gdsc_usb_hsic {
	status = "ok";
};

&gdsc_usb30 {
	status = "ok";
	reg = <0xfc401b80 0x4>;
};

#include "msm-pmd9635-rpm-regulator.dtsi"
#include "msm-pmd9635.dtsi"
#include "mdm9630-regulator.dtsi"

&pmd9635_pon {
	interrupts = <0x0 0x8 0x2>;
	interrupt-names = "cblpwr";
	qcom,system-reset;

	qcom,pon_1 {
		qcom,pon-type = <2>;
		qcom,pull-up = <1>;
		linux,code = <116>;
	};
};

&pmd9635_vadc {
	chan@31 {
		label = "batt_id_therm";
		reg = <0x31>;
		qcom,decimation = <0>;
		qcom,pre-div-channel-scaling = <0>;
		qcom,calibration-type = "ratiometric";
		qcom,scale-function = <0>;
		qcom,hw-settle-time = <2>;
		qcom,fast-avg-setup = <0>;
	};

	chan@33 {
		label = "pa_therm0";
		reg = <0x33>;
		qcom,decimation = <0>;
		qcom,pre-div-channel-scaling = <0>;
		qcom,calibration-type = "ratiometric";
		qcom,scale-function = <2>;
		qcom,hw-settle-time = <2>;
		qcom,fast-avg-setup = <0>;
	};

	chan@34 {
		label = "pa_therm1";
		reg = <0x34>;
		qcom,decimation = <0>;
		qcom,pre-div-channel-scaling = <0>;
		qcom,calibration-type = "ratiometric";
		qcom,scale-function = <2>;
		qcom,hw-settle-time = <2>;
		qcom,fast-avg-setup = <0>;
	};

	chan@32 {
		label = "xo_therm";
		reg = <0x32>;
		qcom,decimation = <0>;
		qcom,pre-div-channel-scaling = <0>;
		qcom,calibration-type = "ratiometric";
		qcom,scale-function = <4>;
		qcom,hw-settle-time = <2>;
		qcom,fast-avg-setup = <0>;
	};

	chan@3c {
		label = "xo_therm_amux";
		reg = <0x3c>;
		qcom,decimation = <0>;
		qcom,pre-div-channel-scaling = <0>;
		qcom,calibration-type = "ratiometric";
		qcom,scale-function = <4>;
		qcom,hw-settle-time = <2>;
		qcom,fast-avg-setup = <0>;
	};

	chan@13 {
		label = "case_therm";
		reg = <0x13>;
		qcom,decimation = <0>;
		qcom,pre-div-channel-scaling = <0>;
		qcom,calibration-type = "ratiometric";
		qcom,scale-function = <2>;
		qcom,hw-settle-time = <2>;
		qcom,fast-avg-setup = <0>;
	};

	chan@15 {
		label = "ambient_therm";
		reg = <0x15>;
		qcom,decimation = <0>;
		qcom,pre-div-channel-scaling = <0>;
		qcom,calibration-type = "ratiometric";
		qcom,scale-function = <2>;
		qcom,hw-settle-time = <2>;
		qcom,fast-avg-setup = <0>;
	};
};

&pmd9635_adc_tm {
	/* Channel Node */
	chan@33 {
		label = "pa_therm0";
		reg = <0x33>;
		qcom,decimation = <0>;
		qcom,pre-div-channel-scaling = <0>;
		qcom,calibration-type = "ratiometric";
		qcom,scale-function = <2>;
		qcom,hw-settle-time = <2>;
		qcom,fast-avg-setup = <0>;
		qcom,btm-channel-number = <0x48>;
		qcom,thermal-node;
	};

	chan@34 {
		label = "pa_therm1";
		reg = <0x34>;
		qcom,decimation = <0>;
		qcom,pre-div-channel-scaling = <0>;
		qcom,calibration-type = "ratiometric";
		qcom,scale-function = <2>;
		qcom,hw-settle-time = <2>;
		qcom,fast-avg-setup = <0>;
		qcom,btm-channel-number = <0x68>;
		qcom,thermal-node;
	};
};
